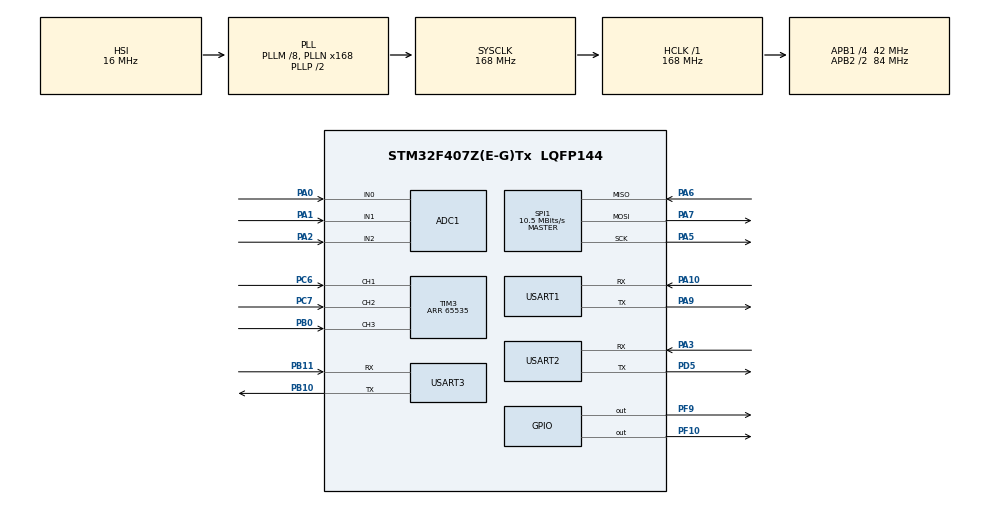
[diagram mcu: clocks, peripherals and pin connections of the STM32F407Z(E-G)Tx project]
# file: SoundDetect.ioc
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ADC1.Channel-0\#ChannelRegularConversion=ADC_CHANNEL_0
ADC1.NbrOfConversionFlag=1
ADC1.Rank-0\#ChannelRegularConversion=1
ADC1.SamplingTime-0\#ChannelRegularConversion=ADC_SAMPLETIME_3CYCLES
ADC1.master=1
FREERTOS.HEAP_NUMBER=4
FREERTOS.Queues01=coreQueue,16,uint8_t,0,Dynamic,NULL,NULL;mainQueue,50,void *,0,Dynamic,NULL,NULL;modemQueue,16,void *,0,Dynamic,NULL,NULL
FREERTOS.Tasks01=coreTask,3,512,app_core,As weak,NULL,Dynamic,NULL,NULL;mainTask,0,1024,app_main,As weak,NULL,Dynamic,NULL,NULL;modemTask,-3,512,app_modem,As weak,NULL,Dynamic,NULL,NULL
FREERTOS.Timers01=timer1,timer1_cb,osTimerPeriodic,As weak,NULL,Dynamic,NULL;timer2,timer2_cb,osTimerPeriodic,As weak,NULL,Dynamic,NULL
FREERTOS.configMINIMAL_STACK_SIZE=256
FREERTOS.configTOTAL_HEAP_SIZE=50000
FREERTOS.configUSE_TIMERS=1
Mcu.Family=STM32F4
Mcu.Name=STM32F407Z(E-G)Tx
Mcu.Package=LQFP144
NVIC.ADC_IRQn=true\:5\:0\:false\:false\:true\:true\:true\:true
NVIC.PriorityGroup=NVIC_PRIORITYGROUP_4
NVIC.TIM4_IRQn=true\:0\:0\:false\:false\:true\:false\:false\:true
NVIC.TimeBase=TIM4_IRQn
NVIC.TimeBaseIP=TIM4
NVIC.USART1_IRQn=true\:5\:0\:false\:false\:true\:true\:true\:true
NVIC.USART2_IRQn=true\:5\:0\:false\:false\:true\:true\:true\:true
NVIC.USART3_IRQn=true\:5\:0\:false\:false\:true\:true\:true\:true
PA0-WKUP.Signal=ADCx_IN0
PA1.Signal=ADCx_IN1
PA10.Mode=Asynchronous
PA10.Signal=USART1_RX
PA13.Mode=Serial_Wire
PA13.Signal=SYS_JTMS-SWDIO
PA14.Mode=Serial_Wire
PA14.Signal=SYS_JTCK-SWCLK
PA2.Signal=ADCx_IN2
PA3.Mode=Asynchronous
PA3.Signal=USART2_RX
PA5.Mode=Full_Duplex_Master
PA5.Signal=SPI1_SCK
PA6.Mode=Full_Duplex_Master
PA6.Signal=SPI1_MISO
PA7.Mode=Full_Duplex_Master
PA7.Signal=SPI1_MOSI
PA9.Mode=Asynchronous
PA9.Signal=USART1_TX
PB0.Signal=S_TIM3_CH3
PB10.Mode=Asynchronous
PB10.Signal=USART3_TX
PB11.Mode=Asynchronous
PB11.Signal=USART3_RX
PC6.Signal=S_TIM3_CH1
PC7.Signal=S_TIM3_CH2
PD5.Mode=Asynchronous
PD5.Signal=USART2_TX
PF10.Signal=GPIO_Output
PF9.Signal=GPIO_Output
PH0-OSC_IN.Mode=HSE-External-Oscillator
PH0-OSC_IN.Signal=RCC_OSC_IN
PH1-OSC_OUT.Mode=HSE-External-Oscillator
PH1-OSC_OUT.Signal=RCC_OSC_OUT
ProjectManager.HeapSize=0x200
ProjectManager.StackSize=0x400
ProjectManager.TargetToolchain=MDK-ARM V5
RCC.48MHZClocksFreq_Value=84000000
RCC.AHBFreq_Value=168000000
RCC.APB1CLKDivider=RCC_HCLK_DIV4
RCC.APB1Freq_Value=42000000
RCC.APB1TimFreq_Value=84000000
RCC.APB2CLKDivider=RCC_HCLK_DIV2
RCC.APB2Freq_Value=84000000
RCC.APB2TimFreq_Value=168000000
RCC.CortexFreq_Value=168000000
RCC.HCLKFreq_Value=168000000
RCC.HSE_VALUE=25000000
RCC.HSI_VALUE=16000000
RCC.LSE_VALUE=32768
RCC.PLLM=8
RCC.PLLN=168
RCC.SYSCLKFreq_VALUE=168000000
RCC.SYSCLKSource=RCC_SYSCLKSOURCE_PLLCLK
RCC.VCOOutputFreq_Value=336000000
SH.ADCx_IN0.0=ADC1_IN0,IN0
SH.ADCx_IN1.0=ADC1_IN1,IN1
SH.ADCx_IN2.0=ADC1_IN2,IN2
SH.S_TIM3_CH1.0=TIM3_CH1,Input_Capture1_from_TI1
SH.S_TIM3_CH2.0=TIM3_CH2,Input_Capture2_from_TI2
SH.S_TIM3_CH3.0=TIM3_CH3,Input_Capture3_from_TI3
SPI1.BaudRatePrescaler=SPI_BAUDRATEPRESCALER_8
SPI1.CalculateBaudRate=10.5 MBits/s
SPI1.Direction=SPI_DIRECTION_2LINES
SPI1.Mode=SPI_MODE_MASTER
SPI1.VirtualType=VM_MASTER
TIM2.Prescaler=0
TIM3.Channel-Input_Capture1_from_TI1=TIM_CHANNEL_1
TIM3.Channel-Input_Capture2_from_TI2=TIM_CHANNEL_2
TIM3.Channel-Input_Capture3_from_TI3=TIM_CHANNEL_3
TIM3.ICFilter_CH1=4
TIM3.ICFilter_CH2=4
TIM3.ICFilter_CH3=4
TIM3.Period=65535
USART1.VirtualMode=VM_ASYNC
USART2.VirtualMode=VM_ASYNC
USART3.VirtualMode=VM_ASYNC
VP_FREERTOS_VS_CMSIS_V1.Mode=CMSIS_V1
VP_SYS_VS_tim4.Mode=TIM4
VP_TIM2_VS_ClockSourceINT.Mode=Internal
board=custom

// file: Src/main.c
/* USER CODE BEGIN Header */
/**
  ******************************************************************************
  * @file           : main.c
  * @brief          : Main program body
  ******************************************************************************
  * @attention
  *
  * <h2><center>&copy; Copyright (c) 2019 STMicroelectronics.
  * All rights reserved.</center></h2>
  *
  * This software component is licensed by ST under Ultimate Liberty license
  * SLA0044, the "License"; You may not use this file except in compliance with
  * the License. You may obtain a copy of the License at:
  *                             www.st.com/SLA0044
  *
  ******************************************************************************
  */
/* USER CODE END Header */

#include "main.h"
#include "cmsis_os.h"

ADC_HandleTypeDef hadc1;

SPI_HandleTypeDef hspi1;

TIM_HandleTypeDef htim2;
TIM_HandleTypeDef htim3;

UART_HandleTypeDef huart1;
UART_HandleTypeDef huart2;
UART_HandleTypeDef huart3;

osThreadId coreTaskHandle;
osThreadId mainTaskHandle;
osThreadId modemTaskHandle;
osMessageQId coreQueueHandle;
osMessageQId mainQueueHandle;
osMessageQId modemQueueHandle;
osTimerId timer1Handle;
osTimerId timer2Handle;

void SystemClock_Config(void);
static void MX_GPIO_Init(void);
static void MX_TIM2_Init(void);
static void MX_ADC1_Init(void);
static void MX_SPI1_Init(void);
static void MX_USART1_UART_Init(void);
static void MX_USART2_UART_Init(void);
static void MX_USART3_UART_Init(void);
static void MX_TIM3_Init(void);
void app_core(void const * argument);
void app_main(void const * argument);
void app_modem(void const * argument);
void timer1_cb(void const * argument);
void timer2_cb(void const * argument);

int main(void)
{

  /* MCU Configuration--------------------------------------------------------*/

  /* Reset of all peripherals, Initializes the Flash interface and the Systick. */
  HAL_Init();

  /* Configure the system clock */
  SystemClock_Config();

  /* Initialize all configured peripherals */
  MX_GPIO_Init();
  MX_TIM2_Init();
  MX_ADC1_Init();
  MX_SPI1_Init();
  MX_USART1_UART_Init();
  MX_USART2_UART_Init();
  MX_USART3_UART_Init();
  MX_TIM3_Init();
  /* USER CODE BEGIN 2 */
	stm32_init();
  /* USER CODE END 2 */

  /* Create the timer(s) */
  /* definition and creation of timer1 */
  osTimerDef(timer1, timer1_cb);
  timer1Handle = osTimerCreate(osTimer(timer1), osTimerPeriodic, NULL);

  /* definition and creation of timer2 */
  osTimerDef(timer2, timer2_cb);
  timer2Handle = osTimerCreate(osTimer(timer2), osTimerPeriodic, NULL);

  /* USER CODE BEGIN RTOS_TIMERS */
  /* start timers, add new ones, ... */
	osTimerStart(timer1Handle, 1);
  /* USER CODE END RTOS_TIMERS */

  /* Create the queue(s) */
  /* definition and creation of coreQueue */
  osMessageQDef(coreQueue, 16, uint8_t);
  coreQueueHandle = osMessageCreate(osMessageQ(coreQueue), NULL);

  /* definition and creation of mainQueue */
  osMessageQDef(mainQueue, 50, void *);
  mainQueueHandle = osMessageCreate(osMessageQ(mainQueue), NULL);

  /* definition and creation of modemQueue */
  osMessageQDef(modemQueue, 16, void *);
  modemQueueHandle = osMessageCreate(osMessageQ(modemQueue), NULL);

  /* Create the thread(s) */
  /* definition and creation of coreTask */
  osThreadDef(coreTask, app_core, osPriorityRealtime, 0, 512);
  coreTaskHandle = osThreadCreate(osThread(coreTask), NULL);

  /* definition and creation of mainTask */
  osThreadDef(mainTask, app_main, osPriorityNormal, 0, 1024);
  mainTaskHandle = osThreadCreate(osThread(mainTask), NULL);

  /* definition and creation of modemTask */
  osThreadDef(modemTask, app_modem, osPriorityIdle, 0, 512);
  modemTaskHandle = osThreadCreate(osThread(modemTask), NULL);

  /* Start scheduler */
  osKernelStart();

  /* We should never get here as control is now taken by the scheduler */

  /* Infinite loop */
  while (1)
  {

  }
}

void SystemClock_Config(void)
{
  RCC_OscInitTypeDef RCC_OscInitStruct = {0};
  RCC_ClkInitTypeDef RCC_ClkInitStruct = {0};

  /** Configure the main internal regulator output voltage
  */
  __HAL_RCC_PWR_CLK_ENABLE();
  __HAL_PWR_VOLTAGESCALING_CONFIG(PWR_REGULATOR_VOLTAGE_SCALE1);
  /** Initializes the CPU, AHB and APB busses clocks
  */
  RCC_OscInitStruct.OscillatorType = RCC_OSCILLATORTYPE_HSI;
  RCC_OscInitStruct.HSIState = RCC_HSI_ON;
  RCC_OscInitStruct.HSICalibrationValue = RCC_HSICALIBRATION_DEFAULT;
  RCC_OscInitStruct.PLL.PLLState = RCC_PLL_ON;
  RCC_OscInitStruct.PLL.PLLSource = RCC_PLLSOURCE_HSI;
  RCC_OscInitStruct.PLL.PLLM = 8;
  RCC_OscInitStruct.PLL.PLLN = 168;
  RCC_OscInitStruct.PLL.PLLP = RCC_PLLP_DIV2;
  RCC_OscInitStruct.PLL.PLLQ = 4;
  if (HAL_RCC_OscConfig(&RCC_OscInitStruct) != HAL_OK)
  {
    Error_Handler();
  }
  /** Initializes the CPU, AHB and APB busses clocks
  */
  RCC_ClkInitStruct.ClockType = RCC_CLOCKTYPE_HCLK|RCC_CLOCKTYPE_SYSCLK
                              |RCC_CLOCKTYPE_PCLK1|RCC_CLOCKTYPE_PCLK2;
  RCC_ClkInitStruct.SYSCLKSource = RCC_SYSCLKSOURCE_PLLCLK;
  RCC_ClkInitStruct.AHBCLKDivider = RCC_SYSCLK_DIV1;
  RCC_ClkInitStruct.APB1CLKDivider = RCC_HCLK_DIV4;
  RCC_ClkInitStruct.APB2CLKDivider = RCC_HCLK_DIV2;

  if (HAL_RCC_ClockConfig(&RCC_ClkInitStruct, FLASH_LATENCY_5) != HAL_OK)
  {
    Error_Handler();
  }
}

static void MX_ADC1_Init(void)
{

  ADC_ChannelConfTypeDef sConfig = {0};

  /** Configure the global features of the ADC (Clock, Resolution, Data Alignment and number of conversion)
  */
  hadc1.Instance = ADC1;
  hadc1.Init.ClockPrescaler = ADC_CLOCK_SYNC_PCLK_DIV4;
  hadc1.Init.Resolution = ADC_RESOLUTION_12B;
  hadc1.Init.ScanConvMode = DISABLE;
  hadc1.Init.ContinuousConvMode = DISABLE;
  hadc1.Init.DiscontinuousConvMode = DISABLE;
  hadc1.Init.ExternalTrigConvEdge = ADC_EXTERNALTRIGCONVEDGE_NONE;
  hadc1.Init.ExternalTrigConv = ADC_SOFTWARE_START;
  hadc1.Init.DataAlign = ADC_DATAALIGN_RIGHT;
  hadc1.Init.NbrOfConversion = 1;
  hadc1.Init.DMAContinuousRequests = DISABLE;
  hadc1.Init.EOCSelection = ADC_EOC_SINGLE_CONV;
  if (HAL_ADC_Init(&hadc1) != HAL_OK)
  {
    Error_Handler();
  }
  /** Configure for the selected ADC regular channel its corresponding rank in the sequencer and its sample time.
  */
  sConfig.Channel = ADC_CHANNEL_0;
  sConfig.Rank = 1;
  sConfig.SamplingTime = ADC_SAMPLETIME_3CYCLES;
  if (HAL_ADC_ConfigChannel(&hadc1, &sConfig) != HAL_OK)
  {
    Error_Handler();
  }

}

static void MX_SPI1_Init(void)
{

  /* SPI1 parameter configuration*/
  hspi1.Instance = SPI1;
  hspi1.Init.Mode = SPI_MODE_MASTER;
  hspi1.Init.Direction = SPI_DIRECTION_2LINES;
  hspi1.Init.DataSize = SPI_DATASIZE_8BIT;
  hspi1.Init.CLKPolarity = SPI_POLARITY_LOW;
  hspi1.Init.CLKPhase = SPI_PHASE_1EDGE;
  hspi1.Init.NSS = SPI_NSS_SOFT;
  hspi1.Init.BaudRatePrescaler = SPI_BAUDRATEPRESCALER_8;
  hspi1.Init.FirstBit = SPI_FIRSTBIT_MSB;
  hspi1.Init.TIMode = SPI_TIMODE_DISABLE;
  hspi1.Init.CRCCalculation = SPI_CRCCALCULATION_DISABLE;
  hspi1.Init.CRCPolynomial = 10;
  if (HAL_SPI_Init(&hspi1) != HAL_OK)
  {
    Error_Handler();
  }

}

static void MX_TIM2_Init(void)
{

  TIM_ClockConfigTypeDef sClockSourceConfig = {0};
  TIM_MasterConfigTypeDef sMasterConfig = {0};

  htim2.Instance = TIM2;
  htim2.Init.Prescaler = 0;
  htim2.Init.CounterMode = TIM_COUNTERMODE_UP;
  htim2.Init.Period = 0;
  htim2.Init.ClockDivision = TIM_CLOCKDIVISION_DIV1;
  htim2.Init.AutoReloadPreload = TIM_AUTORELOAD_PRELOAD_DISABLE;
  if (HAL_TIM_Base_Init(&htim2) != HAL_OK)
  {
    Error_Handler();
  }
  sClockSourceConfig.ClockSource = TIM_CLOCKSOURCE_INTERNAL;
  if (HAL_TIM_ConfigClockSource(&htim2, &sClockSourceConfig) != HAL_OK)
  {
    Error_Handler();
  }
  sMasterConfig.MasterOutputTrigger = TIM_TRGO_RESET;
  sMasterConfig.MasterSlaveMode = TIM_MASTERSLAVEMODE_DISABLE;
  if (HAL_TIMEx_MasterConfigSynchronization(&htim2, &sMasterConfig) != HAL_OK)
  {
    Error_Handler();
  }

}

static void MX_TIM3_Init(void)
{

  TIM_MasterConfigTypeDef sMasterConfig = {0};
  TIM_IC_InitTypeDef sConfigIC = {0};

  htim3.Instance = TIM3;
  htim3.Init.Prescaler = 0;
  htim3.Init.CounterMode = TIM_COUNTERMODE_UP;
  htim3.Init.Period = 65535;
  htim3.Init.ClockDivision = TIM_CLOCKDIVISION_DIV1;
  htim3.Init.AutoReloadPreload = TIM_AUTORELOAD_PRELOAD_DISABLE;
  if (HAL_TIM_IC_Init(&htim3) != HAL_OK)
  {
    Error_Handler();
  }
  sMasterConfig.MasterOutputTrigger = TIM_TRGO_RESET;
  sMasterConfig.MasterSlaveMode = TIM_MASTERSLAVEMODE_DISABLE;
  if (HAL_TIMEx_MasterConfigSynchronization(&htim3, &sMasterConfig) != HAL_OK)
  {
    Error_Handler();
  }
  sConfigIC.ICPolarity = TIM_INPUTCHANNELPOLARITY_RISING;
  sConfigIC.ICSelection = TIM_ICSELECTION_DIRECTTI;
  sConfigIC.ICPrescaler = TIM_ICPSC_DIV1;
  sConfigIC.ICFilter = 4;
  if (HAL_TIM_IC_ConfigChannel(&htim3, &sConfigIC, TIM_CHANNEL_1) != HAL_OK)
  {
    Error_Handler();
  }
  if (HAL_TIM_IC_ConfigChannel(&htim3, &sConfigIC, TIM_CHANNEL_2) != HAL_OK)
  {
    Error_Handler();
  }
  if (HAL_TIM_IC_ConfigChannel(&htim3, &sConfigIC, TIM_CHANNEL_3) != HAL_OK)
  {
    Error_Handler();
  }

}

static void MX_USART1_UART_Init(void)
{

  huart1.Instance = USART1;
  huart1.Init.BaudRate = 115200;
  huart1.Init.WordLength = UART_WORDLENGTH_8B;
  huart1.Init.StopBits = UART_STOPBITS_1;
  huart1.Init.Parity = UART_PARITY_NONE;
  huart1.Init.Mode = UART_MODE_TX_RX;
  huart1.Init.HwFlowCtl = UART_HWCONTROL_NONE;
  huart1.Init.OverSampling = UART_OVERSAMPLING_16;
  if (HAL_UART_Init(&huart1) != HAL_OK)
  {
    Error_Handler();
  }

}

static void MX_USART2_UART_Init(void)
{

  huart2.Instance = USART2;
  huart2.Init.BaudRate = 115200;
  huart2.Init.WordLength = UART_WORDLENGTH_8B;
  huart2.Init.StopBits = UART_STOPBITS_1;
  huart2.Init.Parity = UART_PARITY_NONE;
  huart2.Init.Mode = UART_MODE_TX_RX;
  huart2.Init.HwFlowCtl = UART_HWCONTROL_NONE;
  huart2.Init.OverSampling = UART_OVERSAMPLING_16;
  if (HAL_UART_Init(&huart2) != HAL_OK)
  {
    Error_Handler();
  }

}

static void MX_USART3_UART_Init(void)
{

  huart3.Instance = USART3;
  huart3.Init.BaudRate = 115200;
  huart3.Init.WordLength = UART_WORDLENGTH_8B;
  huart3.Init.StopBits = UART_STOPBITS_1;
  huart3.Init.Parity = UART_PARITY_NONE;
  huart3.Init.Mode = UART_MODE_TX_RX;
  huart3.Init.HwFlowCtl = UART_HWCONTROL_NONE;
  huart3.Init.OverSampling = UART_OVERSAMPLING_16;
  if (HAL_UART_Init(&huart3) != HAL_OK)
  {
    Error_Handler();
  }

}

static void MX_GPIO_Init(void)
{
  GPIO_InitTypeDef GPIO_InitStruct = {0};

  /* GPIO Ports Clock Enable */
  __HAL_RCC_GPIOF_CLK_ENABLE();
  __HAL_RCC_GPIOH_CLK_ENABLE();
  __HAL_RCC_GPIOA_CLK_ENABLE();
  __HAL_RCC_GPIOB_CLK_ENABLE();
  __HAL_RCC_GPIOC_CLK_ENABLE();
  __HAL_RCC_GPIOD_CLK_ENABLE();

  /*Configure GPIO pin Output Level */
  HAL_GPIO_WritePin(GPIOF, GPIO_PIN_9|GPIO_PIN_10, GPIO_PIN_RESET);

  /*Configure GPIO pins : PF9 PF10 */
  GPIO_InitStruct.Pin = GPIO_PIN_9|GPIO_PIN_10;
  GPIO_InitStruct.Mode = GPIO_MODE_OUTPUT_PP;
  GPIO_InitStruct.Pull = GPIO_NOPULL;
  GPIO_InitStruct.Speed = GPIO_SPEED_FREQ_LOW;
  HAL_GPIO_Init(GPIOF, &GPIO_InitStruct);

}

__weak void app_core(void const * argument)
{

  for(;;)
  {
    osDelay(1);
  }
}

__weak void app_main(void const * argument)
{
  for(;;)
  {
    osDelay(1);
  }
}

__weak void app_modem(void const * argument)
{
  for(;;)
  {
    osDelay(1);
  }
}

/* timer1_cb function */
__weak void timer1_cb(void const * argument)
{
}

/* timer2_cb function */
__weak void timer2_cb(void const * argument)
{
}

void HAL_TIM_PeriodElapsedCallback(TIM_HandleTypeDef *htim)
{
  if (htim->Instance == TIM4) {
    HAL_IncTick();
  }
}

void Error_Handler(void)
{
}

/************************ (C) COPYRIGHT STMicroelectronics *****END OF FILE****/
